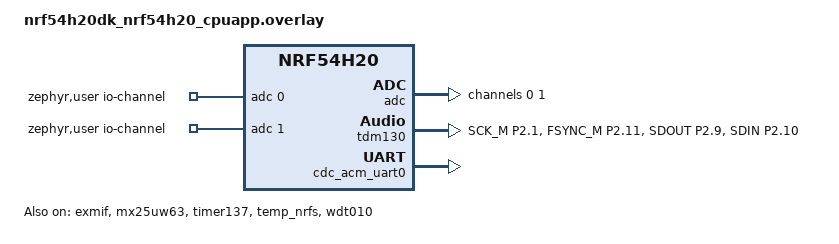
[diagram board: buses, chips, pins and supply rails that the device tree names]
/*
 * Copyright (c) 2024 Nordic Semiconductor ASA
 *
 * SPDX-License-Identifier: LicenseRef-Nordic-5-Clause
 */

/ {
	aliases {
		i2s-node0 = &tdm130;
		test-counter = &timer137;
		watchdog0 = &wdt010;
	};

	zephyr,user {
		io-channels = <&adc 0>, <&adc 1>;
	};
};

&pinctrl {
	tdm130_default_alt: tdm130_default_alt {
		group1 {
			psels = <NRF_PSEL(TDM_SCK_M, 2, 1)>,
				<NRF_PSEL(TDM_FSYNC_M, 2, 11)>,
				<NRF_PSEL(TDM_SDOUT, 2, 9)>,
				<NRF_PSEL(TDM_SDIN, 2, 10)>;
		};
	};
};

&adc {
	#address-cells = <1>;
	#size-cells = <0>;

	channel@0 {
		reg = <0>;
		zephyr,gain = "ADC_GAIN_1_2";
		zephyr,reference = "ADC_REF_INTERNAL";
		zephyr,acquisition-time = <ADC_ACQ_TIME(ADC_ACQ_TIME_MICROSECONDS, 10)>;
		zephyr,input-positive = <NRF_SAADC_AIN4>;
		zephyr,resolution = <10>;
	};

	channel@1 {
		reg = <1>;
		zephyr,gain = "ADC_GAIN_2";
		zephyr,reference = "ADC_REF_EXTERNAL0";
		zephyr,acquisition-time = <ADC_ACQ_TIME(ADC_ACQ_TIME_MICROSECONDS, 10)>;
		zephyr,input-positive = <NRF_SAADC_AIN5>;
		zephyr,resolution = <10>;
	};
};

&gpio6 {
	status = "okay";
	zephyr,pm-device-runtime-auto;
};

&exmif {
	status = "okay";
	zephyr,pm-device-runtime-auto;
};

&mx25uw63 {
	status = "okay";
};

&tdm130 {
	status = "okay";
	pinctrl-0 = <&tdm130_default_alt>;
	pinctrl-names = "default";
	memory-regions = <&cpuapp_dma_region>;
};

&timer137 {
	status = "okay";
	prescaler = <4>;
};

temp_sensor: &temp_nrfs {
	status = "okay";
};

&wdt010 {
	status = "okay";
};

&zephyr_udc0 {
	cdc_acm_uart0 {
		compatible = "zephyr,cdc-acm-uart";
	};
};
